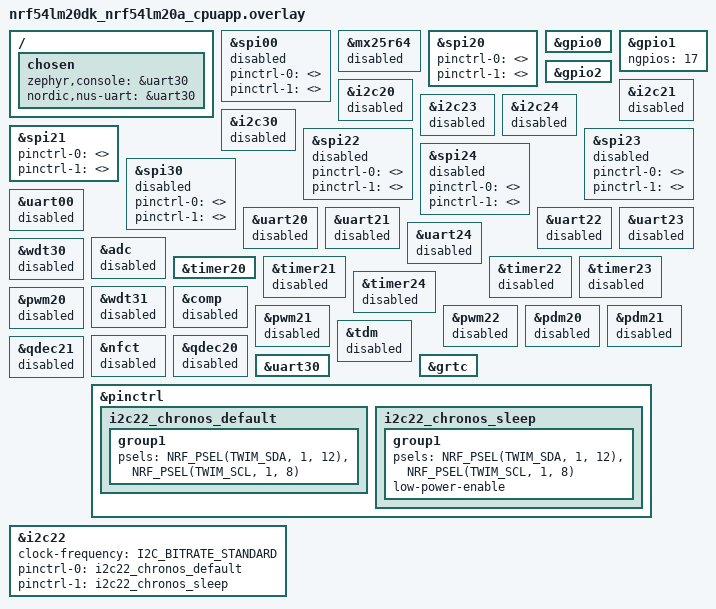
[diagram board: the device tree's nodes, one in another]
/*
 * Copyright (c) 2024 Nordic Semiconductor ASA
 *
 * SPDX-License-Identifier: LicenseRef-Nordic-5-Clause
 */
/*
 * nRF54LM20A: SPIM21 nrfx DAC on P1.11 SCK, P1.10 MOSI, P1.09 CS.
 * UART20 disabled so P1.x available. nrfx configures GPIO+PSEL; no pinctrl for SPI.
 *
 * Chronos application pinout matches the nRF54L15 overlay (same P1/P0 GPIO map).
 * Build: west build -b nrf54lm20dk/nrf54lm20a/cpuapp
 */

/* Disabled: nrfx uses SPIM21; keep mx25r64 disabled to avoid spi00 bus reference. */
&spi00 {
	status = "disabled";
	pinctrl-0 = <>;
	pinctrl-1 = <>;
	pinctrl-names = "default", "sleep";
};
&mx25r64 {
	status = "disabled";
};
/* status = "okay" so SoC domain/clock for SPIM20 is enabled; nrfx drives SPI, no Zephyr SPI driver. */
&spi20 {
	status = "okay";
	pinctrl-0 = <>;
	pinctrl-1 = <>;
	pinctrl-names = "default", "sleep";
};

/* Release NFC pins for GPIO use */
&gpio0 {
	status = "okay";
};
&gpio1 {
	status = "okay";
	ngpios = <17>;
};
&gpio2 {
	status = "okay";
};

/*
 * Power: explicitly disable unused peripherals so they are not initialized
 * (no clocks, no power to those blocks). App uses: uart30, spi20 (nrfx), spi21 (nrfx SPIM21),
 * timer00/10 (nrfx), timer20, gpio, flash/rram.
 * nRF54LM20A labels: i2c20-24/30, spi00/20-24/30, uart00/20-24/30, timer20-24, tdm, etc.
 */
&i2c20 { status = "disabled"; };
&i2c21 { status = "disabled"; };
/* i2c22: AD5933 (SCL P1.08, SDA P1.12). Not i2c21 — same block as nrfx SPIM21. */
&i2c23 { status = "disabled"; };
&i2c24 { status = "disabled"; };
&i2c30 { status = "disabled"; };
/* spi00/spi20 cleared above for nrfx; clear pinctrl on rest to avoid device ord refs. */
&spi21 {
	status = "okay";
	pinctrl-0 = <>;
	pinctrl-1 = <>;
	pinctrl-names = "default", "sleep";
};
&spi22 {
	status = "disabled";
	pinctrl-0 = <>;
	pinctrl-1 = <>;
	pinctrl-names = "default", "sleep";
};
&spi23 {
	status = "disabled";
	pinctrl-0 = <>;
	pinctrl-1 = <>;
	pinctrl-names = "default", "sleep";
};
&spi24 {
	status = "disabled";
	pinctrl-0 = <>;
	pinctrl-1 = <>;
	pinctrl-names = "default", "sleep";
};
&spi30 {
	status = "disabled";
	pinctrl-0 = <>;
	pinctrl-1 = <>;
	pinctrl-names = "default", "sleep";
};
&uart00 { status = "disabled"; };
&uart20 { status = "disabled"; };
&uart21 { status = "disabled"; };
&uart22 { status = "disabled"; };
&uart23 { status = "disabled"; };
&uart24 { status = "disabled"; };
&adc { status = "disabled"; };
&timer20 { status = "okay"; };
&timer21 { status = "disabled"; };
&timer22 { status = "disabled"; };
&timer23 { status = "disabled"; };
&timer24 { status = "disabled"; };
&wdt30 { status = "disabled"; };
&wdt31 { status = "disabled"; };
&comp { status = "disabled"; };
&pwm20 { status = "disabled"; };
&pwm21 { status = "disabled"; };
&pwm22 { status = "disabled"; };
&pdm20 { status = "disabled"; };
&pdm21 { status = "disabled"; };
&tdm { status = "disabled"; };
&nfct { status = "disabled"; };
&qdec20 { status = "disabled"; };
&qdec21 { status = "disabled"; };

/* LFXO: reverted - disabling it increased power on this design. Leave default. */
/* &lfxo { status = "disabled"; }; */
/ {
	chosen {
		zephyr,console = &uart30;
		nordic,nus-uart = &uart30;
	};
};

/* nRF54LM20 DK: UART30 for NUS (overrides board default uart20 console). */
&uart30 {
	status = "okay";
};
&grtc {
	status = "okay";
};

&pinctrl {
	i2c22_chronos_default: i2c22_chronos_default {
		group1 {
			psels = <NRF_PSEL(TWIM_SDA, 1, 12)>,
				<NRF_PSEL(TWIM_SCL, 1, 8)>;
		};
	};

	i2c22_chronos_sleep: i2c22_chronos_sleep {
		group1 {
			psels = <NRF_PSEL(TWIM_SDA, 1, 12)>,
				<NRF_PSEL(TWIM_SCL, 1, 8)>;
			low-power-enable;
		};
	};
};

&i2c22 {
	status = "okay";
	clock-frequency = <I2C_BITRATE_STANDARD>;
	pinctrl-0 = <&i2c22_chronos_default>;
	pinctrl-1 = <&i2c22_chronos_sleep>;
	pinctrl-names = "default", "sleep";
};
